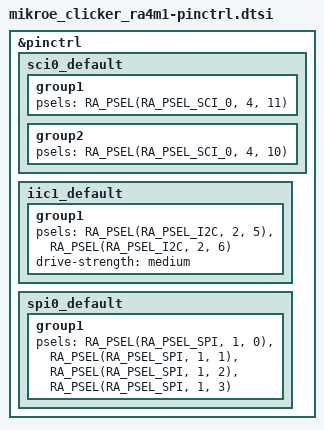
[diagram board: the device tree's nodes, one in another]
/*
 * Copyright (c) 2025 Ian Morris
 *
 * SPDX-License-Identifier: Apache-2.0
 */

&pinctrl {
	sci0_default: sci0_default {
		group1 {
			/* tx */
			psels = <RA_PSEL(RA_PSEL_SCI_0, 4, 11)>;
		};

		group2 {
			/* rx */
			psels = <RA_PSEL(RA_PSEL_SCI_0, 4, 10)>;
		};
	};

	iic1_default: iic1_default {
		group1 {
			/* SCL1 SDA1 */
			psels = <RA_PSEL(RA_PSEL_I2C, 2, 5)>,
				<RA_PSEL(RA_PSEL_I2C, 2, 6)>;
			drive-strength = "medium";
		};
	};

	spi0_default: spi0_default {
		group1 {
			/* MISO MOSI RSPCK SSL */
			psels = <RA_PSEL(RA_PSEL_SPI, 1, 0)>,
				<RA_PSEL(RA_PSEL_SPI, 1, 1)>,
				<RA_PSEL(RA_PSEL_SPI, 1, 2)>,
				<RA_PSEL(RA_PSEL_SPI, 1, 3)>;
		};
	};
};
